# ATxmega128A1 device description
Architecture: AVR8_XMEGA; Family: AVR XMEGA
Registers are 8-bit, access not given, no defined reset value unless marked. A register's access mark holds for its fields unless they carry their own. Offsets are from the block's base; [hi:lo] are bit positions; lines under a group give offsets from that group; {n}, {i} and the like mark numbered series; 'fields as' and 'values as' point back to an identical list.

## RTC — Real-Time Counter
Instances: RTC 0x0400
0x00 CTRL — Control Register
  [2:0] PRESCALER — Prescaling Factor
    0=OFF (RTC Off); 1=DIV1 (RTC Clock); 2=DIV2 (RTC Clock / 2); 3=DIV8 (RTC Clock / 8); 4=DIV16 (RTC Clock / 16); 5=DIV64 (RTC Clock / 64); 6=DIV256 (RTC Clock / 256); 7=DIV1024 (RTC Clock / 1024)
0x01 STATUS
  [0] SYNCBUSY — Synchronization Busy Flag
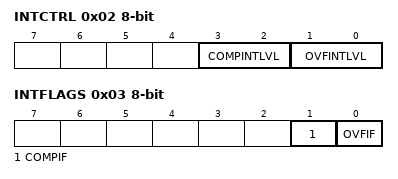
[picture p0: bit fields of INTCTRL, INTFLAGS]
0x02 INTCTRL — Interrupt Control Register
  [3:2] COMPINTLVL — Compare Match Interrupt Level
    0=OFF (Interrupt Disabled); 1=LO (Low Level); 2=MED (Medium Level); 3=HI (High Level)
  [1:0] OVFINTLVL — Overflow Interrupt Level
    values as COMPINTLVL
0x03 INTFLAGS — Interrupt Flags
  [1] COMPIF — Compare Match Interrupt Flag
  [0] OVFIF — Overflow Interrupt Flag
0x04 TEMP — Temporary register
0x08 CNT 16-bit — Count Register
0x0A PER 16-bit — Period Register
0x0C COMP 16-bit — Compare Register

## EBI — External Bus Interface
Instances: EBI 0x0440
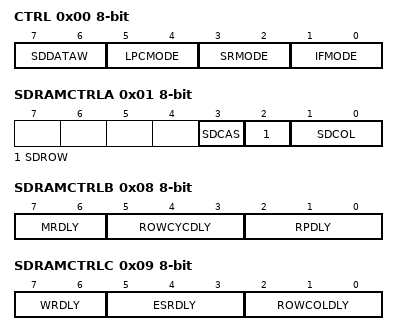
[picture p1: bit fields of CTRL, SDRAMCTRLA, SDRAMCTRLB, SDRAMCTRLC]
0x00 CTRL — Control
  [7:6] SDDATAW — SDRAM Data Width Setting
    0=4BIT (4-bit data bus); 1=8BIT (8-bit data bus)
  [5:4] LPCMODE — SRAM LPC Mode
    0=ALE1 (Data muxed with addr byte 0); 2=ALE12 (Data muxed with addr byte 0 and 1)
  [3:2] SRMODE — SRAM Mode
    0=ALE1 (Addr byte 0 muxed with 1); 1=ALE2 (Addr byte 0 muxed with 2); 2=ALE12 (Addr byte 0 muxed with 1 and 2); 3=NOALE (No addr muxing)
  [1:0] IFMODE — Interface Mode
    0=DISABLED (EBI Disabled); 1=3PORT (3-port mode); 2=4PORT (4-port mode); 3=2PORT (2-port mode)
0x01 SDRAMCTRLA — SDRAM Control Register A
  [3] SDCAS — SDRAM CAS Latency Setting
  [2] SDROW — SDRAM ROW Bits Setting
  [1:0] SDCOL — SDRAM Column Bits Setting
    {v}={v+8}BIT ({v+8} column bits) (v=0..3)
0x04 REFRESH 16-bit — SDRAM Refresh Period
0x06 INITDLY 16-bit — SDRAM Initialization Delay
0x08 SDRAMCTRLB — SDRAM Control Register B
  [7:6] MRDLY — SDRAM Mode Register Delay
    0=0CLK (0 cycles); 1=1CLK (1 cycle); 2=2CLK (2 cycles); 3=3CLK (3 cycles)
  [5:3] ROWCYCDLY — SDRAM Row Cycle Delay
    0=0CLK (0 cycles); 1=1CLK (1 cycle); {v}={v}CLK ({v} cycles) (v=2..7)
  [2:0] RPDLY — SDRAM Row-to-Precharge Delay
    values as ROWCYCDLY
0x09 SDRAMCTRLC — SDRAM Control Register C
  [7:6] WRDLY — SDRAM Write Recovery Delay
    values as SDRAMCTRLB.MRDLY
  [5:3] ESRDLY — SDRAM Exit-Self-refresh-to-Active Delay
    values as SDRAMCTRLB.ROWCYCDLY
  [2:0] ROWCOLDLY — SDRAM Row-to-Column Delay
    values as SDRAMCTRLB.ROWCYCDLY
{0x10+4i} CS{i} group (i=0..3) — Chip Select {i}
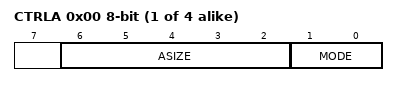
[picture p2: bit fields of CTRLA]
  0x00 CTRLA — Chip Select Control Register A
    [6:2] ASIZE — Address Size
      0=256B (256 bytes); 1=512B (512 bytes); 2=1KB (1K bytes); 3=2KB (2K bytes); 4=4KB (4K bytes); 5=8KB (8K bytes); 6=16KB (16K bytes); 7=32KB (32K bytes); 8=64KB (64K bytes); 9=128KB (128K bytes); 10=256KB (256K bytes); 11=512KB (512K bytes); 12=1MB (1M bytes); 13=2MB (2M bytes); 14=4MB (4M bytes); 15=8MB (8M bytes); 16=16M (16M bytes)
    [1:0] MODE — Memory Mode
      0=DISABLED (Chip Select Disabled); 1=SRAM (Chip Select in SRAM mode); 2=LPC (Chip Select in SRAM LPC mode); 3=SDRAM (Chip Select in SDRAM mode)
  0x01 CTRLB — Chip Select Control Register B
    [7] SDINITDONE — SDRAM Initialization Done
    [2] SDSREN — SDRAM Self-refresh Enable
    [2:0] SRWS — SRAM Wait State Cycles
      values as SDRAMCTRLB.ROWCYCDLY
    [1:0] SDMODE — SDRAM Mode
      0=NORMAL (Normal mode); 1=LOAD (Load Mode Register command mode)
  0x02 BASEADDR 16-bit — Base Address
    [15:4] BASEADDR — Chip Select Base Address

## TWI — Two-Wire Interface
Instances: TWIC 0x480, TWID 0x490, TWIE 0x4A0, TWIF 0x4B0
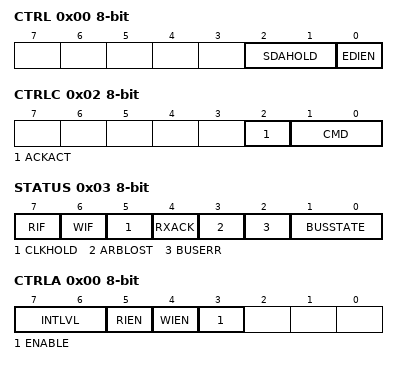
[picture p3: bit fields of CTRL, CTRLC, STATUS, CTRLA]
0x00 CTRL — TWI Common Control Register
  [2:1] SDAHOLD — SDA Hold Time Enable
    0=OFF (SDA hold time off); 1=50NS (Typical 50ns hold time); 2=300NS (Typical 300ns hold time); 3=400NS (Typical 400ns hold time)
  [0] EDIEN — External Driver Interface Enable
0x01 MASTER group — TWI master module
  0x00 CTRLA — Control Register A
    [7:6] INTLVL — Interrupt Level
      0=OFF (Interrupt Disabled); 1=LO (Low Level); 2=MED (Medium Level); 3=HI (High Level)
    [5] RIEN — Read Interrupt Enable
    [4] WIEN — Write Interrupt Enable
    [3] ENABLE — Enable TWI Master
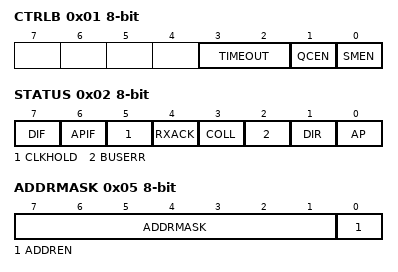
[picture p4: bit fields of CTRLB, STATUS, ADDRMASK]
  0x01 CTRLB — Control Register B
    [3:2] TIMEOUT — Inactive Bus timeout
      0=DISABLED (Bus Timeout Disabled); 1=50US (50 Microseconds); 2=100US (100 Microseconds); 3=200US (200 Microseconds)
    [1] QCEN — Quick Command Enable
    [0] SMEN — Smart Mode Enable
  0x02 CTRLC — Control Register C
    [2] ACKACT — Acknowledge Action
    [1:0] CMD — Command
      0=NOACT (No Action); 1=REPSTART (Issue Repeated Start Condition); 2=RECVTRANS (Receive or Transmit Data); 3=STOP (Issue Stop Condition)
  0x03 STATUS
    [7] RIF — Read Interrupt Flag
    [6] WIF — Write Interrupt Flag
    [5] CLKHOLD — Clock Hold
    [4] RXACK — Received Acknowledge
    [3] ARBLOST — Arbitration Lost
    [2] BUSERR — Bus Error
    [1:0] BUSSTATE
      0=UNKNOWN (Unknown Bus State); 1=IDLE (Bus is Idle); 2=OWNER (This Module Controls The Bus); 3=BUSY (The Bus is Busy)
  0x04 BAUD — Baud Rate Control Register
  0x05 ADDR — Address Register
  0x06 DATA
0x08 SLAVE group — TWI slave module
  0x00 CTRLA — Control Register A
    [7:6] INTLVL — Interrupt Level
      values as MASTER.CTRLA.INTLVL
    [5] DIEN — Data Interrupt Enable
    [4] APIEN — Address/Stop Interrupt Enable
    [3] ENABLE — Enable TWI Slave
    [2] PIEN — Stop Interrupt Enable
    [1] PMEN — Promiscuous Mode Enable
    [0] SMEN — Smart Mode Enable
  0x01 CTRLB — Control Register B
    [2] ACKACT — Acknowledge Action
    [1:0] CMD — Command
      0=NOACT (No Action); 2=COMPTRANS (Used To Complete a Transaction); 3=RESPONSE (Used in Response to Address/Data Interrupt)
  0x02 STATUS
    [7] DIF — Data Interrupt Flag
    [6] APIF — Address/Stop Interrupt Flag
    [5] CLKHOLD — Clock Hold
    [4] RXACK — Received Acknowledge
    [3] COLL — Collision
    [2] BUSERR — Bus Error
    [1] DIR — Read/Write Direction
    [0] AP — Slave Address or Stop
  0x03 ADDR — Address Register
  0x04 DATA
  0x05 ADDRMASK — Address Mask Register
    [7:1] ADDRMASK — Address Mask
    [0] ADDREN — Address Enable
